# VPE_SC register map
Vendor: Texas Instruments
Peripheral module from a debugger description file (folder DRA74xP_75xP_76xP_77xP).
Registers are 32-bit, access per field, reset 0x0 unless marked. A register's access mark holds for its fields unless they carry their own. Offsets are as the file gives them; lines under a group give offsets from that group; [hi:lo] are bit positions; {n}, {i} and the like mark numbered series; 'fields as' and 'values as' point back to an identical list; <NAME> marks a mode.

## VPE_SC
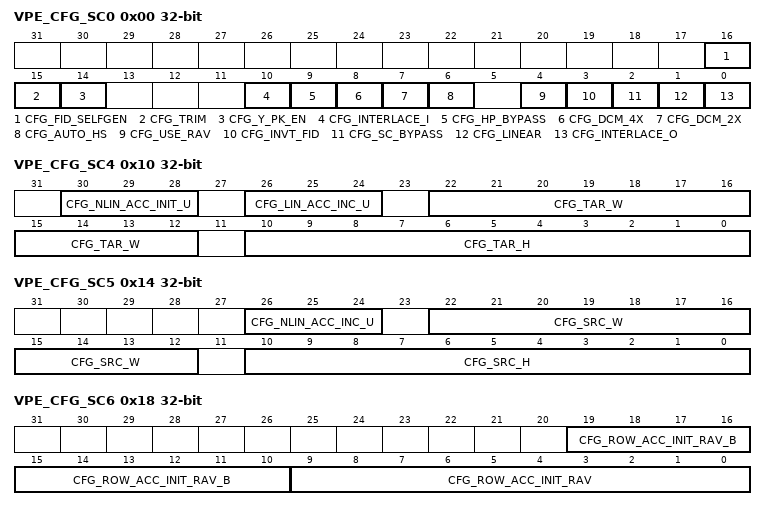
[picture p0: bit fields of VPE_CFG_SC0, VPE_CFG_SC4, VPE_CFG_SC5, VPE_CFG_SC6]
0x00 VPE_CFG_SC0
  [16] CFG_FID_SELFGEN rw — FID self generate enable. When input is progressive and this bit is set, the SC generates self-toggling (top/bottom) output FID when performing interlacing.
  [15] CFG_TRIM rw — Trimming enable. When 1, the input image whose size is specified by orgW and orgH registers is trimmed to the size with srcW and srcH from the offset specified by offW and offH.
    0=Disable_trimming; 1=Enable_trimming
  [14] CFG_Y_PK_EN rw — This parameter is used by peaking block.
    0=disable_luma_peaking; 1=enable_luma_peaking
  [10] CFG_INTERLACE_I rw — This parameter is used by horizontal and vertical scaling.
    0=The_input_video_format_is_progressive; 1=The_input_video_format_is_interlace
  [9] CFG_HP_BYPASS rw — This parameter is used by horizontal scaling. If cfg_auto_hs is 0, horizontal polyphase filter is always enabled. In this case, this register is DON'T CARE. If cfg_auto_hs is 1, then:
    0=The polyphase scaler is always used regardless of the scaling ratio; 1=The polyphase scaler is bypassed only when (tar_w == src_w) or (tar_w == src_w/2) or (tar_w == src_w/4)
  [8] CFG_DCM_4X rw — This parameter is used by horizontal scaling.Note: . (1) Either 2X or 4X can be enabled, but they cannot be enabled simultaneously. . (2) This register is only set to 1 when it makes sense to do so. Typically, it is used when (horizontal scale ratio < 0.25). . (3) This register is DON'T CARE when cfg_auto_hs = 1 .
    0=the_4X_decimation_filter_is_disabled; 1=the_4X_decimation_filter_is_enabled
  [7] CFG_DCM_2X rw — This parameter is used by horizontal scaling.Note: . (1) Either 2X or 4X can be enabled, but they cannot be enabled simultaneously. . (2) This register is only set to 1 when it makes sense to do so. Typically, it is used when (0.25 < horizontal scale ratio < 0.5). . (3) This register is DON'T CARE when cfg_auto_hs = 1. .
    0=the_2X_decimation_filter_is_disabled; 1=the_2X_decimation_filter_is_enabled
  [6] CFG_AUTO_HS rw — This parameter is used by horizontal scaling.SR > 0.5 : horizontal polyphase filter is enabled, all decimation filters are disabled . SR = 0.5 : dcm_2x is enabled, horizontal polyphase filter is enabled or disabled based on cfg_hp_bypass . 0.5 > SR > 0.25 : dcm_2x and horizontal polyphase filter both are enabled . SR = 0.25 : dcm_4x is enabled, horizontal polyphase filter is enabled or disabled based on cfg_hp_bypass . 0.25 > SR > 0.125 : dcm_4x and horizontal polyphase filter are both enabled . SR <= 0.125 : Functionally supported, but not recommended in auto mode for image quality concerns .
    0=the cfg_dcm_2x and cfg_dcm_4x bits will enable appropriate decimation filters; 1=HW_(SR)._1 (HW will decide whether up-scaling or down-scaling is required based on horizontal scaling ratio (SR).)
  [4] CFG_USE_RAV rw — This parameter is used by vertical scaling.
    0=Poly-phase filter will be used for the vertical scaling; 1=Running average filter will be used for the vertical scaling (down scaling only)
  [3] CFG_INVT_FID rw — This parameter is used by vertical scaling.
    0=Progressive_input; 1=CFG_INTERFACE_I_1 (Interlaced input Must be set to 1 when CFG_INTERFACE_I = 1.)
  [2] CFG_SC_BYPASS rw — This parameter is general purpose.
    0=Scaling_module_will_be_engaged; 1=Scaling_module_will_be_bypassed
  [1] CFG_LINEAR rw — This parameter is used by horizontal scaling.
    0=Anamorphic_scaling; 1=Linear_scaling
  [0] CFG_INTERLACE_O rw — This parameter is used by vertical scaling.
    0=SC_0 (The output format of SC is progressive (default);); 1=The_output_format_of_SC_is_interlace
0x04 VPE_CFG_SC1
  [26:0] CFG_ROW_ACC_INC rw — This parameter is used by vertical scaling. It defines the increment of the row accumulator in vertical poly-phase filter. It can be calculated by following formulas:For progressive in/progressive out row_acc_inc = round(2^16*(src_h-1)/(tar_h - 1)) . For progressive_in/interlace_out row_acc_inc = round(2^16*2*(src_h-1)/(2*tar_h - 1)) . For interlace_in/progressive_out row_acc_inc = round(2^16*(2*src_h-1)/(2*(tar_h - 1))) . For interlace_in/interlace_out row_acc_inc = round(2^16*(2*src_h - 1)/(2*tar_h - 1)) . In case of interlaced input, srcH is input field height (number of field lines), as specified in. In case of interlaced output, tarH is output field height (number of field lines), as specified in . .
0x08 VPE_CFG_SC2
  [27:0] CFG_ROW_ACC_OFFSET rw — This parameter is used by vertical scaling. It defines the vertical offset during vertical scaling. In progressive mode: this offset will be applied to a frame. In interlace mode: this offset will be applied to the top field.
0x0C VPE_CFG_SC3
  [27:0] CFG_ROW_ACC_OFFSET_B rw — This parameter is used by vertical scaling. It defines the vertical offset during vertical scaling. In progressive mode: this parameter will not be used. In interlace mode: this offset will be applied to the bottom field.
0x10 VPE_CFG_SC4
  [30:28] CFG_NLIN_ACC_INIT_U rw — This parameter is used by horizontal scaling. The 3 MSBbits of 'nlin_acc_init' that is defined in CFG_SC10
  [26:24] CFG_LIN_ACC_INC_U rw — This parameter is used by horizontal scaling. The 3 MSBbits of 'lin_acc_inc' that is defined in CFG_SC9
  [22:12] CFG_TAR_W rw — This parameter is a general purpose. Scaled target picture width. unit is pixel. This parameter defines the final output picture size
  [10:0] CFG_TAR_H rw — This parameter is a general purpose. Scaled target picture height (unit is line). This parameter defines the final output picture size. For the interlace output, it should be the number of lines per field.
0x14 VPE_CFG_SC5
  [26:24] CFG_NLIN_ACC_INC_U rw — This parameter is used by horizontal scaling. The 3 MSBbits of 'nlin_acc_inc' that is defined in CFG_SC11
  [22:12] CFG_SRC_W rw — This parameter is a general purpose. This parameter defines the width of the source image
  [10:0] CFG_SRC_H rw — This parameter is a general purpose. This parameter defines the height of the source image. For the interlace input, it should be the number of lines per field.
0x18 VPE_CFG_SC6
  [19:10] CFG_ROW_ACC_INIT_RAV_B rw — This parameter is used by vertical scaling. it is used only when the input is interlace format. In vertical down scaling.. the running average filter is applied. This parameter sets the initialization value of the row accumulator in running average filter (for bottom field of interlace format)
  [9:0] CFG_ROW_ACC_INIT_RAV rw — This parameter is used by vertical scaling. In vertical down scaling.. the running average filter is applied. This parameter sets the initialization value of the row accumulator in running average filter (for progressive format or top field of interlace format)
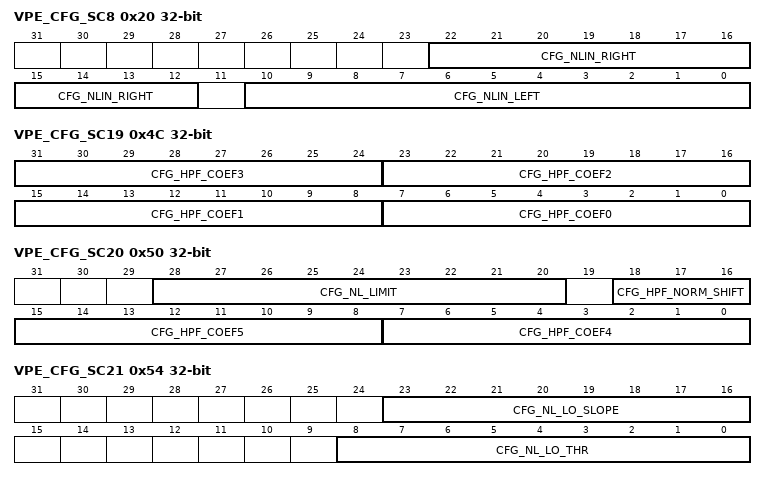
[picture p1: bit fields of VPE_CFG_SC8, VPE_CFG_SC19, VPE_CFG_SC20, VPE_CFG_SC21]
0x20 VPE_CFG_SC8
  [22:12] CFG_NLIN_RIGHT rw — This parameter is used by horizontal scaling. In anamorphic mode. this parameter defines the width of the strip on right-hand side. In other words. it defines the location of the last pixel where the linear scaling is ended. The unit is the 'pixel location' in an active video line. This parameter will not be used in linear scaling
  [10:0] CFG_NLIN_LEFT rw — This parameter is used by horizontal scaling. In anamorphic mode. this parameter defines the width of the strip on left-hand side. In other words. it defines the location of the last pixel in the left-sidenonlinear strip. The unit is the 'pixel location' in an active video line. This parameter will not be used in linear scaling
0x24 VPE_CFG_SC9 rw
  [31:0] CFG_LIN_ACC_INC — This parameter is used by horizontal scaling. It defines the increment of the linear accumulator. if SR &gt; 0.5, then else if 0.25 &lt; SR &lt;= 0.5 else if SR &lt;= 0.25 where srcWi and tarWi are the inner source width and the inner target width respectively.
0x28 VPE_CFG_SC10 rw
  [31:0] CFG_NLIN_ACC_INIT — This parameter is used by horizontal scaling. It is used by nonlinear scaling only. It defines the initialization value of the nonlinear accumulator. nlin_acc_init = K*(1-2*d) Here the definitions of K and d are the same as in CFG_SC11
0x2C VPE_CFG_SC11 rw
  [31:0] CFG_NLIN_ACC_INC — This parameter is used by horizontal scaling. It is used by nonlinear scaling only. It defines the increment of the nonlinear accumulator. if upscaling then d = 0 if Ltar !=0 then K =round[2*Lsrc/(Ltar*Ltar) ] where Lsrc= (srcW-srcWi)/2 else K = 0 elseif downscaling d = (tarW-1)/2 if Ltar!=0 then K = round[ 2 * Lsrc / (Ltar*(Ltar-2d))] where Lsrc= (srcW-srcWi)/(2n) and n=1..2 or 4 else K = 0 nlin_acc_inc = 2*K (negative for downscaling)
0x30 VPE_CFG_SC12
  [24:0] CFG_COL_ACC_OFFSET rw — This parameter is used in horizontal scaling. It defines the luma accumulator's offset. Normally this parameter can be set as 0 if no horizontal offset is involved. In some applications, such as Pan and Scan. A corresponding offset value should be set. The format is 1.24.
0x34 VPE_CFG_SC13
  [9:0] CFG_SC_FACTOR_RAV rw — This parameter is used by vertical scaling. Vertical scaling factor: It is defined as following: 1024*tarH/srcH. It is used for downscaling by the running average filter
0x48 VPE_CFG_SC18
  [9:0] CFG_HS_FACTOR rw — This parameter is used by horizontal scaling. Horizontal-scaling-factor = tarWi/srcWi. Numerical format: 6.4 (6 bit integer and 4 bit fraction)
0x4C VPE_CFG_SC19 rw
  [8n+7:8n] CFG_HPF_COEF{n} (n=0..3) — This parameter is used by the peaking block. Defines the coefficient {n} of the HPF used in the peaking filter. Signed. Decimal point is defined by hpf_norm_shift.
0x50 VPE_CFG_SC20
  [28:20] CFG_NL_LIMIT rw — This parameter is used by the peaking block. The maximum of clipping.
  [18:16] CFG_HPF_NORM_SHIFT rw — This parameter is used by the peaking block. Defines the decimal point of the hpf coefficient.
  [15:8] CFG_HPF_COEF5 rw — This parameter is used by the peaking block. Defines the coefficient 5 of the HPF used in the peaking filter. Signed. Decimal point is defined by hpf_norm_shift.
  [7:0] CFG_HPF_COEF4 rw — This parameter is used by the peaking block. Defines the coefficient 4 of the HPF used in the peaking filter. Signed. Decimal point is defined by hpf_norm_shift.
0x54 VPE_CFG_SC21
  [23:16] CFG_NL_LO_SLOPE rw — This parameter is used by the peaking block. Slope of the nonlinear peaking function. The format is fixed point 4.4.
  [8:0] CFG_NL_LO_THR rw — This parameter is used by the peaking block. Threshold for the nonlinear peaking function. Must be 0
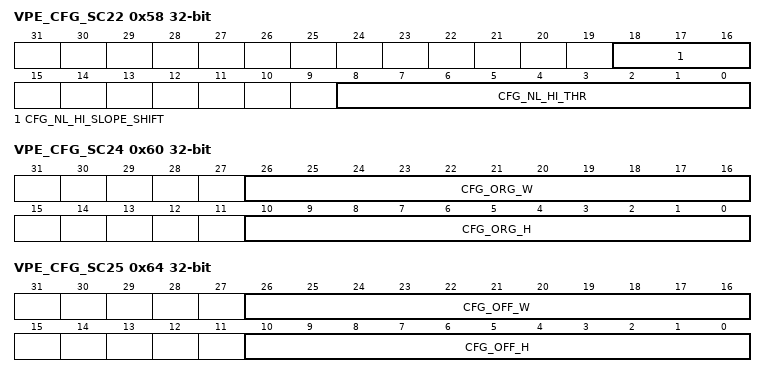
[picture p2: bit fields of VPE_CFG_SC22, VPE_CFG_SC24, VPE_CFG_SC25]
0x58 VPE_CFG_SC22
  [18:16] CFG_NL_HI_SLOPE_SHIFT rw — This parameter is used by the peaking block. Slope of the nonlinear peaking function. The gain is 2.
  [8:0] CFG_NL_HI_THR rw — This parameter is used by the peaking block. Threshold for the nonlinear peaking function. Must be nl_hi_thr.
0x60 VPE_CFG_SC24
  [26:16] CFG_ORG_W rw — This parameter is used by the trimmer. Horizontal offset from the left of the original input image.
  [10:0] CFG_ORG_H rw — This parameter is used by the trimmer. Vertical offset from the top of the original input image.
0x64 VPE_CFG_SC25
  [26:16] CFG_OFF_W rw — This parameter is used by the trimmer. Horizontal offset from the left of the original input image.
  [10:0] CFG_OFF_H rw — This parameter is used by the trimmer. Vertical offset from the top of the original input image.
